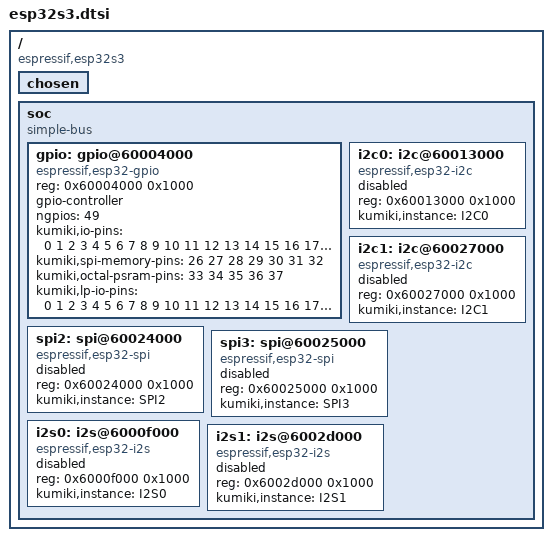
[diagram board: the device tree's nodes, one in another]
/*
 * ESP32S3 SoC (subset used by kumiki board definitions).
 * @generated by `kumiki-dtgen soc-dtsi` from:
 *   esp-metadata-generated 0.5.3 (src/_generated_esp32s3.rs): GPIOs, I2C / SPI masters, octal PSRAM pins
 *   esp32s3 0.36.0 (PAC src/lib.rs): base addresses
 * Do not edit by hand.
 */

/ {
	#address-cells = <1>;
	#size-cells = <1>;
	compatible = "espressif,esp32s3";

	chosen {
	};

	soc {
		#address-cells = <1>;
		#size-cells = <1>;
		compatible = "simple-bus";
		ranges;

		gpio: gpio@60004000 {
			compatible = "espressif,esp32-gpio";
			reg = <0x60004000 0x1000>;
			gpio-controller;
			#gpio-cells = <2>;
			ngpios = <49>;
			/* Not bonded out: 22 23 24 25. */
			/* Pins the HAL exposes. */
			kumiki,io-pins = <0 1 2 3 4 5 6 7 8 9 10 11 12 13 14 15 16 17 18 19 20 21 26 27 28 29 30 31 32 33 34 35 36 37 38 39 40 41 42 43 44 45 46 47 48>;
			/* May be owned by the SPI flash / quad PSRAM: never handed to the application. */
			kumiki,spi-memory-pins = <26 27 28 29 30 31 32>;
			/* May be owned by embedded octal PSRAM (eFuse PSRAM_CAP). */
			kumiki,octal-psram-pins = <33 34 35 36 37>;
			/* RTC / LP IOs: powered in deep sleep, can wake the chip from it. */
			kumiki,lp-io-pins = <0 1 2 3 4 5 6 7 8 9 10 11 12 13 14 15 16 17 18 19 20 21>;
		};

		i2c0: i2c@60013000 {
			compatible = "espressif,esp32-i2c";
			reg = <0x60013000 0x1000>;
			#address-cells = <1>;
			#size-cells = <0>;
			kumiki,instance = "I2C0";
			status = "disabled";
		};

		i2c1: i2c@60027000 {
			compatible = "espressif,esp32-i2c";
			reg = <0x60027000 0x1000>;
			#address-cells = <1>;
			#size-cells = <0>;
			kumiki,instance = "I2C1";
			status = "disabled";
		};

		spi2: spi@60024000 {
			compatible = "espressif,esp32-spi";
			reg = <0x60024000 0x1000>;
			#address-cells = <1>;
			#size-cells = <0>;
			kumiki,instance = "SPI2";
			status = "disabled";
		};

		spi3: spi@60025000 {
			compatible = "espressif,esp32-spi";
			reg = <0x60025000 0x1000>;
			#address-cells = <1>;
			#size-cells = <0>;
			kumiki,instance = "SPI3";
			status = "disabled";
		};

		i2s0: i2s@6000f000 {
			compatible = "espressif,esp32-i2s";
			reg = <0x6000f000 0x1000>;
			#address-cells = <1>;
			#size-cells = <0>;
			kumiki,instance = "I2S0";
			status = "disabled";
		};

		i2s1: i2s@6002d000 {
			compatible = "espressif,esp32-i2s";
			reg = <0x6002d000 0x1000>;
			#address-cells = <1>;
			#size-cells = <0>;
			kumiki,instance = "I2S1";
			status = "disabled";
		};
	};
};
